# uart_ctrl_reg_db: IP-XACT component
VLNV Cadence_Design_Systems:uart_ctrl_lib:uart_ctrl_reg_db:1.0

## Address spaces and blocks
uart_ctrl_reg_model.uart_ctrl_rf: base 0x00, range 0xFFFF, width 8

## Registers
Registers are 8-bit, read-write, reset 0x0 unless marked. A register's access mark holds for its fields unless they carry their own. Offsets are from the block's base; lines under a group give offsets from that group; [hi:lo] are bit positions; {n}, {i} and the like mark numbered series; 'fields as' and 'values as' point back to an identical list; <NAME> marks a mode.

## uart_ctrl_reg_model.uart_ctrl_rf
Base 0x00000000
0x00 ua_div_latch0
  [7:0] div_val
0x01 ua_div_latch1
  [7:0] div_val
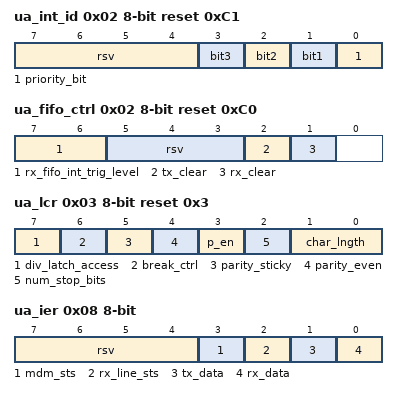
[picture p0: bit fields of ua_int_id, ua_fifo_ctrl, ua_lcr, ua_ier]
0x02 ua_int_id ro reset 0xC1
  [7:4] rsv, [3] bit3, [2] bit2, [1] bit1, [0] priority_bit
0x02 ua_fifo_ctrl wo reset 0xC0
  [7:6] rx_fifo_int_trig_level, [5:3] rsv, [2] tx_clear, [1] rx_clear
0x03 ua_lcr reset 0x3
  [7] div_latch_access, [6] break_ctrl, [5] parity_sticky, [4] parity_even, [3] p_en, [2] num_stop_bits, [1:0] char_lngth
0x08 ua_ier (reset mask 0xF)
  [7:4] rsv, [3] mdm_sts, [2] rx_line_sts, [1] tx_data, [0] rx_data
